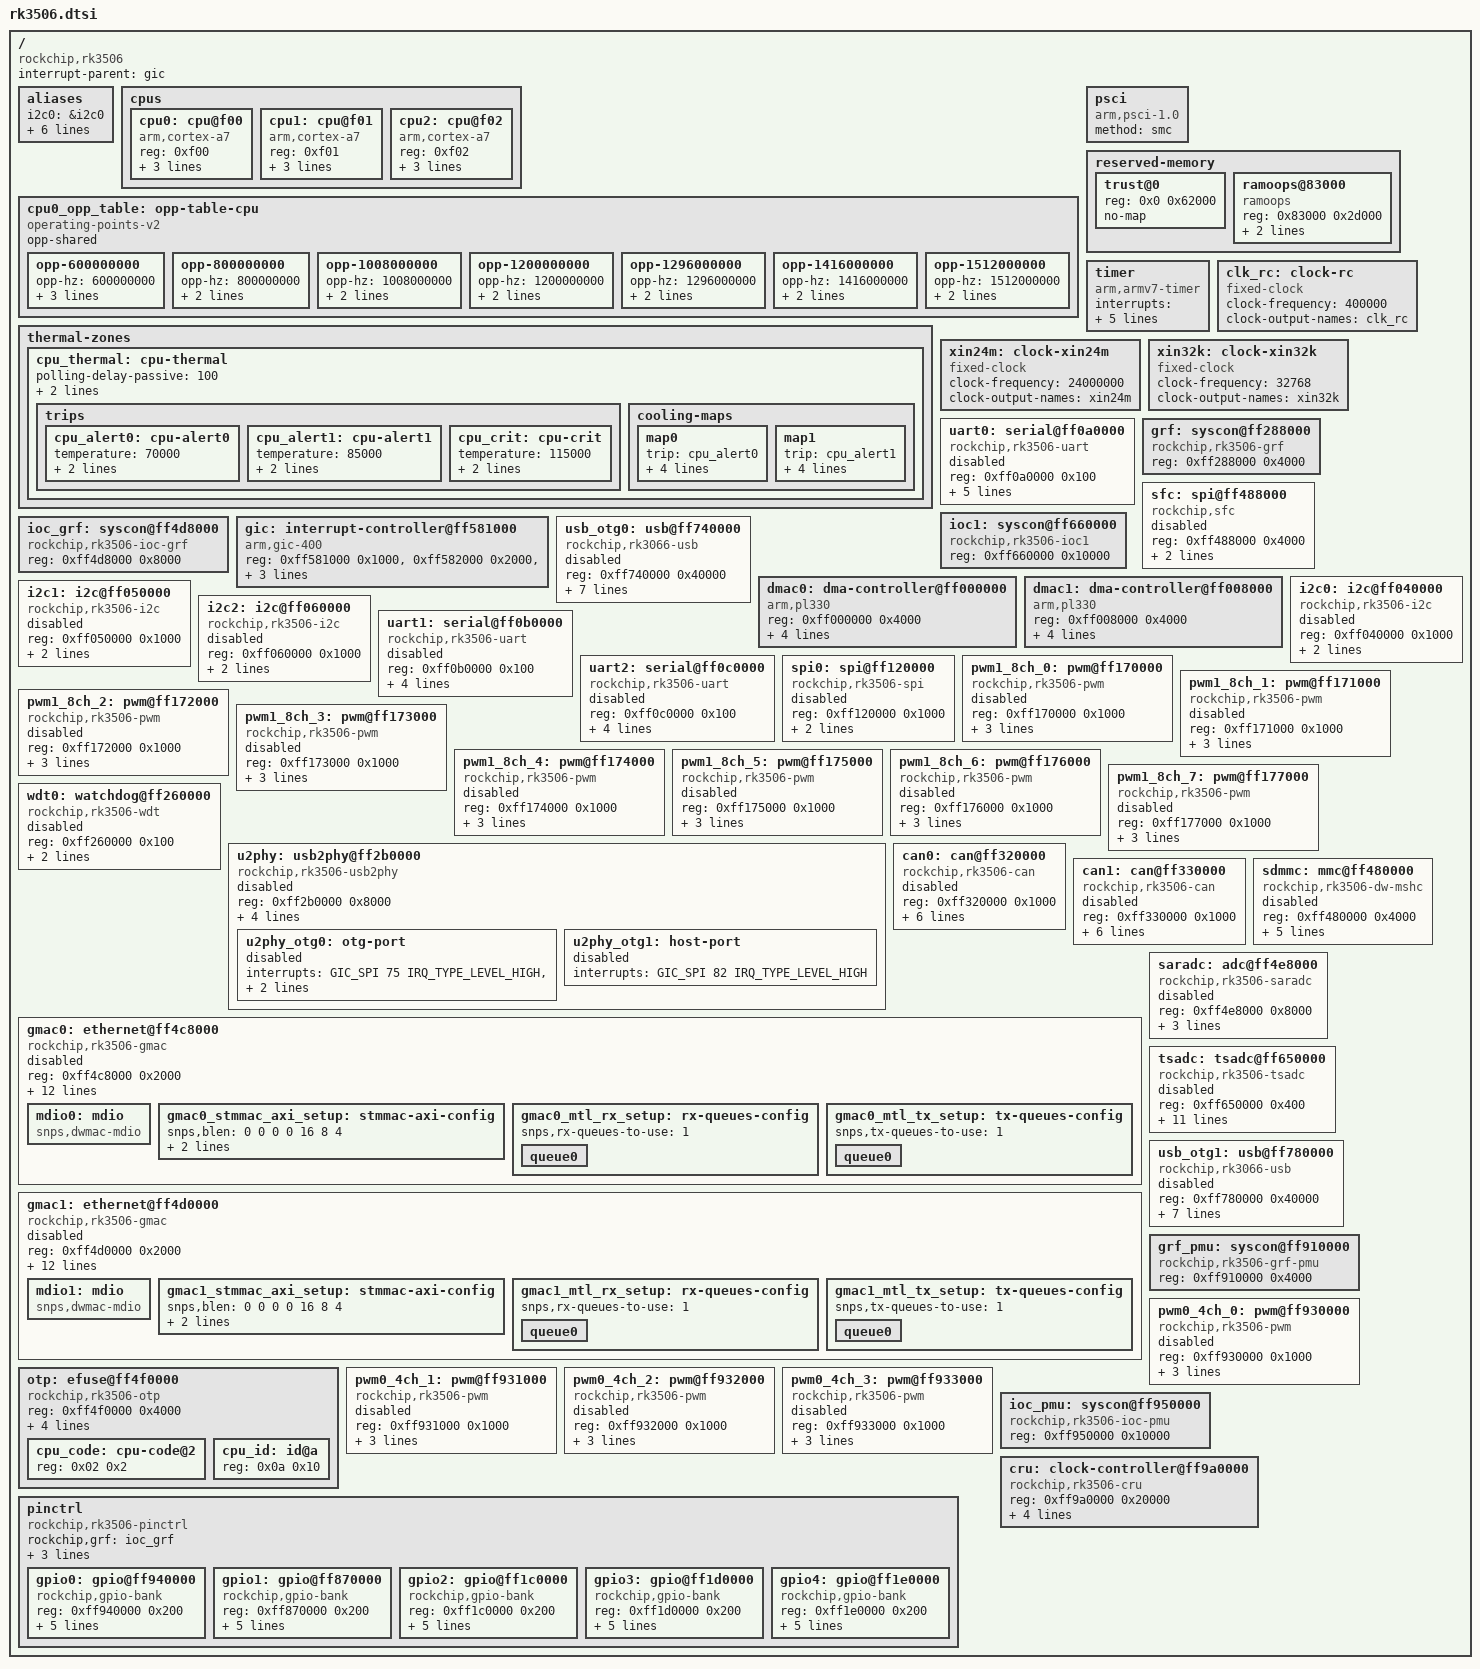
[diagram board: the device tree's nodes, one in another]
// SPDX-License-Identifier: (GPL-2.0+ OR MIT)
/*
 * Copyright (c) 2023 Rockchip Electronics Co., Ltd.
 *
 * Minimal RK3506 SoC description: only what is needed to reach a prompt on
 * the serial console. Transcribed from the vendor 6.1 kernel,
 * arch/arm/boot/dts/rk3502.dtsi (the real base dtsi there; rk3506.dtsi is a
 * thin wrapper on top of it).
 *
 * Deliberately absent: audio, PWM, mailbox, hwspinlock, USB, flexbus,
 * crypto, RNG, RGA, TSADC, SARADC, OTP, MMC, FSPI, DMA, I2C, SPI, uart1..5,
 * watchdog, OPP tables, PMU, thermal and the Rockchip-only suspend and
 * system-monitor nodes. Every one of those is a probe that can fail before
 * the console is up.
 */

#include <dt-bindings/clock/rockchip,rk3506-cru.h>
#include <dt-bindings/reset/rockchip,rk3506-cru.h>
#include <dt-bindings/gpio/gpio.h>
#include <dt-bindings/interrupt-controller/irq.h>
#include <dt-bindings/thermal/thermal.h>
#include <dt-bindings/interrupt-controller/arm-gic.h>
#include <dt-bindings/pinctrl/rockchip.h>

/ {
	#address-cells = <1>;
	#size-cells = <1>;

	compatible = "rockchip,rk3506";

	interrupt-parent = <&gic>;

	aliases {
		i2c0 = &i2c0;
		i2c1 = &i2c1;
		i2c2 = &i2c2;
		serial0 = &uart0;
		serial1 = &uart1;
		serial2 = &uart2;
		spi0 = &spi0;
	};

	cpus {
		#address-cells = <1>;
		#size-cells = <0>;

		cpu0: cpu@f00 {
			device_type = "cpu";
			compatible = "arm,cortex-a7";
			reg = <0xf00>;
			enable-method = "psci";
			clocks = <&cru ARMCLK>;
			operating-points-v2 = <&cpu0_opp_table>;
			#cooling-cells = <2>;
		};

		cpu1: cpu@f01 {
			device_type = "cpu";
			compatible = "arm,cortex-a7";
			reg = <0xf01>;
			enable-method = "psci";
			clocks = <&cru ARMCLK>;
			operating-points-v2 = <&cpu0_opp_table>;
			#cooling-cells = <2>;
		};

		cpu2: cpu@f02 {
			device_type = "cpu";
			compatible = "arm,cortex-a7";
			reg = <0xf02>;
			enable-method = "psci";
			clocks = <&cru ARMCLK>;
			operating-points-v2 = <&cpu0_opp_table>;
			#cooling-cells = <2>;
		};
	};

	/*
	 * The vendor tree's points and base voltages (it lowers them per chip
	 * from OTP data, which is not modelled here). armclk re-rates v1pll for
	 * each point and parks the cores on gpll meanwhile.
	 */
	cpu0_opp_table: opp-table-cpu {
		compatible = "operating-points-v2";
		opp-shared;

		opp-600000000 {
			opp-hz = /bits/ 64 <600000000>;
			opp-microvolt = <850000 850000 1207000>;
			clock-latency-ns = <40000>;
			opp-suspend;
		};

		opp-800000000 {
			opp-hz = /bits/ 64 <800000000>;
			opp-microvolt = <850000 850000 1207000>;
			clock-latency-ns = <40000>;
		};

		opp-1008000000 {
			opp-hz = /bits/ 64 <1008000000>;
			opp-microvolt = <850000 850000 1207000>;
			clock-latency-ns = <40000>;
		};

		opp-1200000000 {
			opp-hz = /bits/ 64 <1200000000>;
			opp-microvolt = <850000 850000 1207000>;
			clock-latency-ns = <40000>;
		};

		opp-1296000000 {
			opp-hz = /bits/ 64 <1296000000>;
			opp-microvolt = <900000 900000 1207000>;
			clock-latency-ns = <40000>;
		};

		opp-1416000000 {
			opp-hz = /bits/ 64 <1416000000>;
			opp-microvolt = <937500 937500 1207000>;
			clock-latency-ns = <40000>;
		};

		opp-1512000000 {
			opp-hz = /bits/ 64 <1512000000>;
			opp-microvolt = <975000 975000 1207000>;
			clock-latency-ns = <40000>;
		};
	};

	psci {
		compatible = "arm,psci-1.0";
		method = "smc";
	};

	thermal-zones {
		cpu_thermal: cpu-thermal {
			polling-delay-passive = <100>;
			polling-delay = <1000>;
			thermal-sensors = <&tsadc 0>;

			trips {
				cpu_alert0: cpu-alert0 {
					temperature = <70000>;
					hysteresis = <2000>;
					type = "passive";
				};
				cpu_alert1: cpu-alert1 {
					temperature = <85000>;
					hysteresis = <2000>;
					type = "passive";
				};
				cpu_crit: cpu-crit {
					temperature = <115000>;
					hysteresis = <2000>;
					type = "critical";
				};
			};

			cooling-maps {
				map0 {
					trip = <&cpu_alert0>;
					cooling-device = <&cpu0 THERMAL_NO_LIMIT THERMAL_NO_LIMIT>,
							 <&cpu1 THERMAL_NO_LIMIT THERMAL_NO_LIMIT>,
							 <&cpu2 THERMAL_NO_LIMIT THERMAL_NO_LIMIT>;
				};
				map1 {
					trip = <&cpu_alert1>;
					cooling-device = <&cpu0 THERMAL_NO_LIMIT THERMAL_NO_LIMIT>,
							 <&cpu1 THERMAL_NO_LIMIT THERMAL_NO_LIMIT>,
							 <&cpu2 THERMAL_NO_LIMIT THERMAL_NO_LIMIT>;
				};
			};
		};
	};

	reserved-memory {
		#address-cells = <1>;
		#size-cells = <1>;
		ranges;

		/*
		 * OP-TEE / TF-A. Do not remove: psci method = "smc" is served
		 * from here, so handing this range to the page allocator kills
		 * SMP bring-up and PSCI system-off.
		 *
		 * no-map because the range is not merely reserved, it is
		 * unreachable: the memory firewall rejects normal-world
		 * access, and even a read aborts. Measured from the U-Boot
		 * prompt, which also runs in normal world:
		 *
		 *     => md 0x4000 4
		 *     00004000:data abort
		 *
		 * The vendor node (rk3502.dtsi:335) omits no-map and so leaves
		 * the range in the kernel linear map, i.e. mappings that must
		 * never be touched.
		 */
		trust@0 {
			reg = <0x0 0x62000>;
			no-map;
		};

		/*
		 * The only way to read a panic that happened before the
		 * console was up. Vendor also sets boot-log-size and
		 * boot-log-count (rk3502.dtsi:352) - those are Rockchip
		 * extensions with no mainline binding, dropped here.
		 *
		 * The address is below the 2 MiB floor that
		 * linux,usable-memory-range establishes in the board dts, and
		 * that is fine: capping memblock removes the range from the
		 * allocator, not from reserved-memory. Verified on the board,
		 * pstore comes up and uses this region.
		 */
		ramoops@83000 {
			compatible = "ramoops";
			reg = <0x83000 0x2d000>;
			console-size = <0x20000>;
			record-size = <0x1000>;
		};
	};

	timer {
		compatible = "arm,armv7-timer";
		interrupts = <GIC_PPI 13 (GIC_CPU_MASK_SIMPLE(3) | IRQ_TYPE_LEVEL_HIGH)>,
			     <GIC_PPI 14 (GIC_CPU_MASK_SIMPLE(3) | IRQ_TYPE_LEVEL_HIGH)>,
			     <GIC_PPI 11 (GIC_CPU_MASK_SIMPLE(3) | IRQ_TYPE_LEVEL_HIGH)>,
			     <GIC_PPI 10 (GIC_CPU_MASK_SIMPLE(3) | IRQ_TYPE_LEVEL_HIGH)>;
		clock-frequency = <24000000>;
	};

	/*
	 * clk_rc, xin24m and xin32k are consumed by the CRU driver through
	 * their global names, not through a phandle, and the driver does not
	 * register them itself:
	 *   clk-rk3506.c:745  CLK_32K_RC ("clk_rc" parent, CLK_IS_CRITICAL)
	 *   clk-rk3506.c:175  XIN24M_GATE ("xin24m" parent, CLK_IS_CRITICAL)
	 *   clk-rk3506.c:145  clk_32k mux ("xin32k" parent)
	 * All three must therefore exist in DT even though no node here has a
	 * phandle to them. Vendor wraps them in a "clocks" simple-bus
	 * container (rk3502.dtsi:44); flattened to the root here, which is the
	 * mainline form and avoids dtc simple_bus_reg warnings. Same names,
	 * same rates, same labels.
	 */
	clk_rc: clock-rc {
		compatible = "fixed-clock";
		#clock-cells = <0>;
		clock-frequency = <400000>;
		clock-output-names = "clk_rc";
	};

	xin24m: clock-xin24m {
		compatible = "fixed-clock";
		#clock-cells = <0>;
		clock-frequency = <24000000>;
		clock-output-names = "xin24m";
	};

	xin32k: clock-xin32k {
		compatible = "fixed-clock";
		#clock-cells = <0>;
		clock-frequency = <32768>;
		clock-output-names = "xin32k";
	};

	uart0: serial@ff0a0000 {
		compatible = "rockchip,rk3506-uart", "snps,dw-apb-uart";
		reg = <0xff0a0000 0x100>;
		interrupts = <GIC_SPI 34 IRQ_TYPE_LEVEL_HIGH>;
		reg-shift = <2>;
		reg-io-width = <4>;
		clocks = <&cru SCLK_UART0>, <&cru PCLK_UART0>;
		clock-names = "baudclk", "apb_pclk";
		pinctrl-names = "default";
		pinctrl-0 = <&uart0_xfer_pins>;
		status = "disabled";
		/* vendor also wires dmas to dmac0; no DMA controller here */
	};

	grf: syscon@ff288000 {
		compatible = "rockchip,rk3506-grf", "syscon";
		reg = <0xff288000 0x4000>;
	};

	/*
	 * Serial flash controller. The vendor calls this block FSPI and gives
	 * it its own compatible ("rockchip,rk3506-fspi", "rockchip,fspi",
	 * rk3502.dtsi:942), but it keeps the SFC clock names, and the mainline
	 * binding states that the SFC is "a standalone IP with version
	 * register, and the driver can handle all the feature difference
	 * inside the IP depending on the version register". So describe it as
	 * rockchip,sfc and let spi-rockchip-sfc.c read SFC_VER.
	 *
	 * The vendor node also carries rockchip,grf and rockchip,max-dll,
	 * which the mainline binding does not define; left out.
	 */
	sfc: spi@ff488000 {
		compatible = "rockchip,sfc";
		reg = <0xff488000 0x4000>;
		interrupts = <GIC_SPI 85 IRQ_TYPE_LEVEL_HIGH>;
		clocks = <&cru SCLK_FSPI>, <&cru HCLK_FSPI>;
		clock-names = "clk_sfc", "hclk_sfc";
		#address-cells = <1>;
		#size-cells = <0>;
		status = "disabled";
	};

	/* pinctrl "rockchip,grf": iomux registers for the non-PMU banks */
	ioc_grf: syscon@ff4d8000 {
		compatible = "rockchip,rk3506-ioc-grf", "syscon";
		reg = <0xff4d8000 0x8000>;
	};

	gic: interrupt-controller@ff581000 {
		compatible = "arm,gic-400";
		reg = <0xff581000 0x1000>,
		      <0xff582000 0x2000>,
		      <0xff584000 0x2000>,
		      <0xff586000 0x2000>;
		interrupts = <GIC_PPI 9 IRQ_TYPE_LEVEL_HIGH>;
		#interrupt-cells = <3>;
		interrupt-controller;
		#address-cells = <0>;
	};

	/* pinctrl "rockchip,ioc1" */
	ioc1: syscon@ff660000 {
		compatible = "rockchip,rk3506-ioc1", "syscon";
		reg = <0xff660000 0x10000>;
	};

	/*
	 * OTG0, the USB port exposed on the board. No "phys" property: the
	 * RK3506 USB2 PHY is not supported by phy-rockchip-inno-usb2 yet, and
	 * dwc2 treats the PHY as optional (dwc2/platform.c, -ENODEV leaves
	 * hsotg->phy NULL and the probe continues).
	 *
	 * Only the "otg" clock is declared: dwc2.yaml allows just "otg" and
	 * "utmi", while the vendor also wires a "pmu" and an "adp" clock that
	 * mainline never touches.
	 *
	 * The compatible omits a "rockchip,rk3506-usb" first entry on purpose:
	 * dwc2.yaml enumerates the SoC-specific strings it accepts and rk3506
	 * is not among them, so adding it here without the binding change
	 * would only make dtbs_check fail.
	 */
	usb_otg0: usb@ff740000 {
		compatible = "rockchip,rk3066-usb", "snps,dwc2";
		reg = <0xff740000 0x40000>;
		interrupts = <GIC_SPI 74 IRQ_TYPE_LEVEL_HIGH>;
		clocks = <&cru HCLK_USBOTG0>;
		clock-names = "otg";
		dr_mode = "otg";
		g-np-tx-fifo-size = <16>;
		g-rx-fifo-size = <280>;
		g-tx-fifo-size = <256 128 128 64 32 16>;
		phys = <&u2phy_otg0>;
		phy-names = "usb2-phy";
		status = "disabled";
	};


	dmac0: dma-controller@ff000000 {
		compatible = "arm,pl330", "arm,primecell";
		reg = <0xff000000 0x4000>;
		interrupts = <GIC_SPI 116 IRQ_TYPE_LEVEL_HIGH>,
			     <GIC_SPI 117 IRQ_TYPE_LEVEL_HIGH>;
		clocks = <&cru ACLK_DMAC0>;
		clock-names = "apb_pclk";
		#dma-cells = <1>;
		arm,pl330-periph-burst;
	};

	dmac1: dma-controller@ff008000 {
		compatible = "arm,pl330", "arm,primecell";
		reg = <0xff008000 0x4000>;
		interrupts = <GIC_SPI 118 IRQ_TYPE_LEVEL_HIGH>,
			     <GIC_SPI 119 IRQ_TYPE_LEVEL_HIGH>;
		clocks = <&cru ACLK_DMAC1>;
		clock-names = "apb_pclk";
		#dma-cells = <1>;
		arm,pl330-periph-burst;
	};

	i2c0: i2c@ff040000 {
		compatible = "rockchip,rk3506-i2c", "rockchip,rk3399-i2c";
		reg = <0xff040000 0x1000>;
		interrupts = <GIC_SPI 40 IRQ_TYPE_LEVEL_HIGH>;
		clocks = <&cru CLK_I2C0>, <&cru PCLK_I2C0>;
		clock-names = "i2c", "pclk";
		#address-cells = <1>;
		#size-cells = <0>;
		status = "disabled";
	};

	i2c1: i2c@ff050000 {
		compatible = "rockchip,rk3506-i2c", "rockchip,rk3399-i2c";
		reg = <0xff050000 0x1000>;
		interrupts = <GIC_SPI 41 IRQ_TYPE_LEVEL_HIGH>;
		clocks = <&cru CLK_I2C1>, <&cru PCLK_I2C1>;
		clock-names = "i2c", "pclk";
		#address-cells = <1>;
		#size-cells = <0>;
		status = "disabled";
	};

	i2c2: i2c@ff060000 {
		compatible = "rockchip,rk3506-i2c", "rockchip,rk3399-i2c";
		reg = <0xff060000 0x1000>;
		interrupts = <GIC_SPI 42 IRQ_TYPE_LEVEL_HIGH>;
		clocks = <&cru CLK_I2C2>, <&cru PCLK_I2C2>;
		clock-names = "i2c", "pclk";
		#address-cells = <1>;
		#size-cells = <0>;
		status = "disabled";
	};

	uart1: serial@ff0b0000 {
		compatible = "rockchip,rk3506-uart", "snps,dw-apb-uart";
		reg = <0xff0b0000 0x100>;
		interrupts = <GIC_SPI 35 IRQ_TYPE_LEVEL_HIGH>;
		clocks = <&cru SCLK_UART1>, <&cru PCLK_UART1>;
		clock-names = "baudclk", "apb_pclk";
		reg-shift = <2>;
		reg-io-width = <4>;
		status = "disabled";
	};

	uart2: serial@ff0c0000 {
		compatible = "rockchip,rk3506-uart", "snps,dw-apb-uart";
		reg = <0xff0c0000 0x100>;
		interrupts = <GIC_SPI 36 IRQ_TYPE_LEVEL_HIGH>;
		clocks = <&cru SCLK_UART2>, <&cru PCLK_UART2>;
		clock-names = "baudclk", "apb_pclk";
		reg-shift = <2>;
		reg-io-width = <4>;
		status = "disabled";
	};

	spi0: spi@ff120000 {
		compatible = "rockchip,rk3506-spi", "rockchip,rk3066-spi";
		reg = <0xff120000 0x1000>;
		interrupts = <GIC_SPI 43 IRQ_TYPE_LEVEL_HIGH>;
		clocks = <&cru CLK_SPI0>, <&cru PCLK_SPI0>;
		clock-names = "spiclk", "apb_pclk";
		#address-cells = <1>;
		#size-cells = <0>;
		status = "disabled";
	};

	pwm1_8ch_0: pwm@ff170000 {
		compatible = "rockchip,rk3506-pwm", "rockchip,rk3576-pwm";
		reg = <0xff170000 0x1000>;
		clocks = <&cru CLK_PWM1>, <&cru PCLK_PWM1>, <&cru CLK_OSC_PWM1>,
			 <&cru CLK_RC_PWM1>;
		clock-names = "pwm", "pclk", "osc", "rc";
		interrupts = <GIC_SPI 26 IRQ_TYPE_LEVEL_HIGH>;
		#pwm-cells = <3>;
		status = "disabled";
	};

	pwm1_8ch_1: pwm@ff171000 {
		compatible = "rockchip,rk3506-pwm", "rockchip,rk3576-pwm";
		reg = <0xff171000 0x1000>;
		clocks = <&cru CLK_PWM1>, <&cru PCLK_PWM1>, <&cru CLK_OSC_PWM1>,
			 <&cru CLK_RC_PWM1>;
		clock-names = "pwm", "pclk", "osc", "rc";
		interrupts = <GIC_SPI 27 IRQ_TYPE_LEVEL_HIGH>;
		#pwm-cells = <3>;
		status = "disabled";
	};

	pwm1_8ch_2: pwm@ff172000 {
		compatible = "rockchip,rk3506-pwm", "rockchip,rk3576-pwm";
		reg = <0xff172000 0x1000>;
		clocks = <&cru CLK_PWM1>, <&cru PCLK_PWM1>, <&cru CLK_OSC_PWM1>,
			 <&cru CLK_RC_PWM1>;
		clock-names = "pwm", "pclk", "osc", "rc";
		interrupts = <GIC_SPI 28 IRQ_TYPE_LEVEL_HIGH>;
		#pwm-cells = <3>;
		status = "disabled";
	};

	pwm1_8ch_3: pwm@ff173000 {
		compatible = "rockchip,rk3506-pwm", "rockchip,rk3576-pwm";
		reg = <0xff173000 0x1000>;
		clocks = <&cru CLK_PWM1>, <&cru PCLK_PWM1>, <&cru CLK_OSC_PWM1>,
			 <&cru CLK_RC_PWM1>;
		clock-names = "pwm", "pclk", "osc", "rc";
		interrupts = <GIC_SPI 29 IRQ_TYPE_LEVEL_HIGH>;
		#pwm-cells = <3>;
		status = "disabled";
	};

	pwm1_8ch_4: pwm@ff174000 {
		compatible = "rockchip,rk3506-pwm", "rockchip,rk3576-pwm";
		reg = <0xff174000 0x1000>;
		clocks = <&cru CLK_PWM1>, <&cru PCLK_PWM1>, <&cru CLK_OSC_PWM1>,
			 <&cru CLK_RC_PWM1>;
		clock-names = "pwm", "pclk", "osc", "rc";
		interrupts = <GIC_SPI 30 IRQ_TYPE_LEVEL_HIGH>;
		#pwm-cells = <3>;
		status = "disabled";
	};

	pwm1_8ch_5: pwm@ff175000 {
		compatible = "rockchip,rk3506-pwm", "rockchip,rk3576-pwm";
		reg = <0xff175000 0x1000>;
		clocks = <&cru CLK_PWM1>, <&cru PCLK_PWM1>, <&cru CLK_OSC_PWM1>,
			 <&cru CLK_RC_PWM1>;
		clock-names = "pwm", "pclk", "osc", "rc";
		interrupts = <GIC_SPI 31 IRQ_TYPE_LEVEL_HIGH>;
		#pwm-cells = <3>;
		status = "disabled";
	};

	pwm1_8ch_6: pwm@ff176000 {
		compatible = "rockchip,rk3506-pwm", "rockchip,rk3576-pwm";
		reg = <0xff176000 0x1000>;
		clocks = <&cru CLK_PWM1>, <&cru PCLK_PWM1>, <&cru CLK_OSC_PWM1>,
			 <&cru CLK_RC_PWM1>;
		clock-names = "pwm", "pclk", "osc", "rc";
		interrupts = <GIC_SPI 32 IRQ_TYPE_LEVEL_HIGH>;
		#pwm-cells = <3>;
		status = "disabled";
	};

	pwm1_8ch_7: pwm@ff177000 {
		compatible = "rockchip,rk3506-pwm", "rockchip,rk3576-pwm";
		reg = <0xff177000 0x1000>;
		clocks = <&cru CLK_PWM1>, <&cru PCLK_PWM1>, <&cru CLK_OSC_PWM1>,
			 <&cru CLK_RC_PWM1>;
		clock-names = "pwm", "pclk", "osc", "rc";
		interrupts = <GIC_SPI 33 IRQ_TYPE_LEVEL_HIGH>;
		#pwm-cells = <3>;
		status = "disabled";
	};

	wdt0: watchdog@ff260000 {
		compatible = "rockchip,rk3506-wdt", "snps,dw-wdt";
		reg = <0xff260000 0x100>;
		interrupts = <GIC_SPI 107 IRQ_TYPE_LEVEL_HIGH>;
		clocks = <&cru TCLK_WDT0>, <&cru PCLK_WDT0>;
		clock-names = "tclk", "pclk";
		status = "disabled";
	};

	u2phy: usb2phy@ff2b0000 {
		compatible = "rockchip,rk3506-usb2phy";
		reg = <0xff2b0000 0x8000>;
		clocks = <&cru CLK_REF_USBPHY_TOP>, <&cru PCLK_USBPHY>;
		clock-names = "phyclk", "pclk";
		clock-output-names = "usb480m_phy";
		#clock-cells = <0>;
		rockchip,usbgrf = <&grf>;
		status = "disabled";

		u2phy_otg0: otg-port {
			#phy-cells = <0>;
			interrupts = <GIC_SPI 75 IRQ_TYPE_LEVEL_HIGH>,
				     <GIC_SPI 76 IRQ_TYPE_LEVEL_HIGH>,
				     <GIC_SPI 77 IRQ_TYPE_LEVEL_HIGH>;
			interrupt-names = "otg-bvalid", "otg-id", "linestate";
			status = "disabled";
		};

		u2phy_otg1: host-port {
			#phy-cells = <0>;
			interrupts = <GIC_SPI 82 IRQ_TYPE_LEVEL_HIGH>;
			interrupt-names = "linestate";
			status = "disabled";
		};
	};

	can0: can@ff320000 {
		compatible = "rockchip,rk3506-can", "rockchip,rk3576-can";
		reg = <0xff320000 0x1000>;
		interrupts = <GIC_SPI 45 IRQ_TYPE_LEVEL_HIGH>;
		clocks = <&cru CLK_CAN0>, <&cru HCLK_CAN0>;
		clock-names = "baudclk", "apb_pclk";
		/* keep the bit clock off v1pll, which cpufreq re-rates */
		assigned-clocks = <&cru CLK_CAN0>;
		assigned-clock-parents = <&cru CLK_V0PLL_GATE>;
		assigned-clock-rates = <300000000>;
		resets = <&cru SRST_CAN0>, <&cru SRST_H_CAN0>;
		reset-names = "can", "can-apb";
		status = "disabled";
	};

	can1: can@ff330000 {
		compatible = "rockchip,rk3506-can", "rockchip,rk3576-can";
		reg = <0xff330000 0x1000>;
		interrupts = <GIC_SPI 46 IRQ_TYPE_LEVEL_HIGH>;
		clocks = <&cru CLK_CAN1>, <&cru HCLK_CAN1>;
		clock-names = "baudclk", "apb_pclk";
		/* keep the bit clock off v1pll, which cpufreq re-rates */
		assigned-clocks = <&cru CLK_CAN1>;
		assigned-clock-parents = <&cru CLK_V0PLL_GATE>;
		assigned-clock-rates = <300000000>;
		resets = <&cru SRST_CAN1>, <&cru SRST_H_CAN1>;
		reset-names = "can", "can-apb";
		status = "disabled";
	};

	sdmmc: mmc@ff480000 {
		compatible = "rockchip,rk3506-dw-mshc", "rockchip,rk3288-dw-mshc";
		reg = <0xff480000 0x4000>;
		interrupts = <GIC_SPI 86 IRQ_TYPE_LEVEL_HIGH>;
		clocks = <&cru HCLK_SDMMC>, <&cru CCLK_SRC_SDMMC>;
		clock-names = "biu", "ciu";
		fifo-depth = <0x100>;
		max-frequency = <150000000>;
		resets = <&cru SRST_H_SDMMC>;
		reset-names = "reset";
		status = "disabled";
	};

	gmac0: ethernet@ff4c8000 {
		compatible = "rockchip,rk3506-gmac", "snps,dwmac-4.20a";
		reg = <0xff4c8000 0x2000>;
		interrupts = <GIC_SPI 66 IRQ_TYPE_LEVEL_HIGH>,
			     <GIC_SPI 69 IRQ_TYPE_LEVEL_HIGH>;
		interrupt-names = "macirq", "eth_wake_irq";
		clocks = <&cru CLK_MAC0>, <&cru CLK_MAC0_PTP>,
			 <&cru PCLK_MAC0>, <&cru ACLK_MAC0>,
			 <&cru CLK_MAC_OUT>;
		clock-names = "stmmaceth", "ptp_ref", "pclk_mac", "aclk_mac", "clk_mac_out";
		resets = <&cru SRST_A_MAC0>;
		reset-names = "stmmaceth";
		rockchip,grf = <&grf>;
		snps,axi-config = <&gmac0_stmmac_axi_setup>;
		snps,mixed-burst;
		snps,mtl-rx-config = <&gmac0_mtl_rx_setup>;
		snps,mtl-tx-config = <&gmac0_mtl_tx_setup>;
		snps,tso;
		status = "disabled";

		mdio0: mdio {
			compatible = "snps,dwmac-mdio";
			#address-cells = <0x1>;
			#size-cells = <0x0>;
		};

		gmac0_stmmac_axi_setup: stmmac-axi-config {
			snps,blen = <0 0 0 0 16 8 4>;
			snps,rd_osr_lmt = <8>;
			snps,wr_osr_lmt = <4>;
		};

		gmac0_mtl_rx_setup: rx-queues-config {
			snps,rx-queues-to-use = <1>;
			queue0 {};
		};

		gmac0_mtl_tx_setup: tx-queues-config {
			snps,tx-queues-to-use = <1>;
			queue0 {};
		};
	};

	gmac1: ethernet@ff4d0000 {
		compatible = "rockchip,rk3506-gmac", "snps,dwmac-4.20a";
		reg = <0xff4d0000 0x2000>;
		interrupts = <GIC_SPI 70 IRQ_TYPE_LEVEL_HIGH>,
			     <GIC_SPI 73 IRQ_TYPE_LEVEL_HIGH>;
		interrupt-names = "macirq", "eth_wake_irq";
		clocks = <&cru CLK_MAC1>, <&cru CLK_MAC1_PTP>,
			 <&cru PCLK_MAC1>, <&cru ACLK_MAC1>,
			 <&cru CLK_MAC_OUT>;
		clock-names = "stmmaceth", "ptp_ref", "pclk_mac", "aclk_mac", "clk_mac_out";
		resets = <&cru SRST_A_MAC1>;
		reset-names = "stmmaceth";
		rockchip,grf = <&grf>;
		snps,axi-config = <&gmac1_stmmac_axi_setup>;
		snps,mixed-burst;
		snps,mtl-rx-config = <&gmac1_mtl_rx_setup>;
		snps,mtl-tx-config = <&gmac1_mtl_tx_setup>;
		snps,tso;
		status = "disabled";

		mdio1: mdio {
			compatible = "snps,dwmac-mdio";
			#address-cells = <0x1>;
			#size-cells = <0x0>;
		};

		gmac1_stmmac_axi_setup: stmmac-axi-config {
			snps,blen = <0 0 0 0 16 8 4>;
			snps,rd_osr_lmt = <8>;
			snps,wr_osr_lmt = <4>;
		};

		gmac1_mtl_rx_setup: rx-queues-config {
			snps,rx-queues-to-use = <1>;
			queue0 {};
		};

		gmac1_mtl_tx_setup: tx-queues-config {
			snps,tx-queues-to-use = <1>;
			queue0 {};
		};
	};

	saradc: adc@ff4e8000 {
		compatible = "rockchip,rk3506-saradc", "rockchip,rk3528-saradc";
		reg = <0xff4e8000 0x8000>;
		interrupts = <GIC_SPI 57 IRQ_TYPE_LEVEL_HIGH>;
		clocks = <&cru CLK_SARADC>, <&cru PCLK_SARADC>;
		clock-names = "saradc", "apb_pclk";
		resets = <&cru SRST_P_SARADC>;
		reset-names = "saradc-apb";
		#io-channel-cells = <1>;
		status = "disabled";
	};

	otp: efuse@ff4f0000 {
		compatible = "rockchip,rk3506-otp";
		reg = <0xff4f0000 0x4000>;
		clocks = <&cru CLK_USER_OTPC_NS>, <&cru PCLK_OTPC_NS>,
			 <&cru CLK_SBPI_OTPC_NS>;
		clock-names = "otp", "apb_pclk", "sbpi";
		resets = <&cru SRST_USER_OTPC_NS>, <&cru SRST_P_OTPC_NS>,
			 <&cru SRST_SBPI_OTPC_NS>;
		reset-names = "otp", "apb", "sbpi";
		#address-cells = <1>;
		#size-cells = <1>;

		cpu_code: cpu-code@2 {
			reg = <0x02 0x2>;
		};

		cpu_id: id@a {
			reg = <0x0a 0x10>;
		};
	};

	tsadc: tsadc@ff650000 {
		compatible = "rockchip,rk3506-tsadc";
		reg = <0xff650000 0x400>;
		interrupts = <GIC_SPI 58 IRQ_TYPE_LEVEL_HIGH>;
		clocks = <&cru CLK_TSADC>, <&cru PCLK_TSADC>, <&cru CLK_TSADC_TSEN>;
		clock-names = "tsadc", "apb_pclk", "tsen";
		assigned-clocks = <&cru CLK_TSADC>, <&cru CLK_TSADC_TSEN>;
		assigned-clock-rates = <1000000>, <12000000>;
		resets = <&cru SRST_P_TSADC>, <&cru SRST_TSADC>;
		reset-names = "tsadc-apb", "tsadc";
		rockchip,grf = <&grf>;
		rockchip,hw-tshut-temp = <120000>;
		rockchip,hw-tshut-mode = <0>;
		rockchip,hw-tshut-polarity = <0>;
		#thermal-sensor-cells = <1>;
		status = "disabled";
	};

	usb_otg1: usb@ff780000 {
		compatible = "rockchip,rk3066-usb", "snps,dwc2";
		reg = <0xff780000 0x40000>;
		interrupts = <GIC_SPI 79 IRQ_TYPE_LEVEL_HIGH>;
		clocks = <&cru HCLK_USBOTG1>;
		clock-names = "otg";
		dr_mode = "otg";
		g-np-tx-fifo-size = <16>;
		g-rx-fifo-size = <280>;
		g-tx-fifo-size = <256 128 128 64 32 16>;
		phys = <&u2phy_otg1>;
		phy-names = "usb2-phy";
		status = "disabled";
	};

	/*
	 * pinctrl "rockchip,rmio". Mandatory for this SoC:
	 * pinctrl-rockchip.c returns -EINVAL when the phandle is missing,
	 * because rk3506_pin_ctrl declares one rmio region.
	 * The vendor reboot-mode child is dropped (needs
	 * <dt-bindings/soc/rockchip,boot-mode.h> and adds nothing to a
	 * console bring-up).
	 */
	grf_pmu: syscon@ff910000 {
		compatible = "rockchip,rk3506-grf-pmu", "syscon";
		reg = <0xff910000 0x4000>;
	};

	pwm0_4ch_0: pwm@ff930000 {
		compatible = "rockchip,rk3506-pwm", "rockchip,rk3576-pwm";
		reg = <0xff930000 0x1000>;
		clocks = <&cru CLK_PWM0>, <&cru PCLK_PWM0>, <&cru CLK_OSC_PWM0>,
			 <&cru CLK_RC_PWM0>;
		clock-names = "pwm", "pclk", "osc", "rc";
		interrupts = <GIC_SPI 22 IRQ_TYPE_LEVEL_HIGH>;
		#pwm-cells = <3>;
		status = "disabled";
	};

	pwm0_4ch_1: pwm@ff931000 {
		compatible = "rockchip,rk3506-pwm", "rockchip,rk3576-pwm";
		reg = <0xff931000 0x1000>;
		clocks = <&cru CLK_PWM0>, <&cru PCLK_PWM0>, <&cru CLK_OSC_PWM0>,
			 <&cru CLK_RC_PWM0>;
		clock-names = "pwm", "pclk", "osc", "rc";
		interrupts = <GIC_SPI 23 IRQ_TYPE_LEVEL_HIGH>;
		#pwm-cells = <3>;
		status = "disabled";
	};

	pwm0_4ch_2: pwm@ff932000 {
		compatible = "rockchip,rk3506-pwm", "rockchip,rk3576-pwm";
		reg = <0xff932000 0x1000>;
		clocks = <&cru CLK_PWM0>, <&cru PCLK_PWM0>, <&cru CLK_OSC_PWM0>,
			 <&cru CLK_RC_PWM0>;
		clock-names = "pwm", "pclk", "osc", "rc";
		interrupts = <GIC_SPI 24 IRQ_TYPE_LEVEL_HIGH>;
		#pwm-cells = <3>;
		status = "disabled";
	};

	pwm0_4ch_3: pwm@ff933000 {
		compatible = "rockchip,rk3506-pwm", "rockchip,rk3576-pwm";
		reg = <0xff933000 0x1000>;
		clocks = <&cru CLK_PWM0>, <&cru PCLK_PWM0>, <&cru CLK_OSC_PWM0>,
			 <&cru CLK_RC_PWM0>;
		clock-names = "pwm", "pclk", "osc", "rc";
		interrupts = <GIC_SPI 25 IRQ_TYPE_LEVEL_HIGH>;
		#pwm-cells = <3>;
		status = "disabled";
	};

	/* pinctrl "rockchip,pmu": iomux registers for the PMU bank (gpio0) */
	ioc_pmu: syscon@ff950000 {
		compatible = "rockchip,rk3506-ioc-pmu", "syscon";
		reg = <0xff950000 0x10000>;
	};

	cru: clock-controller@ff9a0000 {
		compatible = "rockchip,rk3506-cru";
		reg = <0xff9a0000 0x20000>;
		clocks = <&xin24m>;
		clock-names = "xin";
		#clock-cells = <1>;
		#reset-cells = <1>;

		/*
		 * Kept from the vendor node: SCLK_UART0 can only reach
		 * 1500000 baud through one of these fractional matrices.
		 */
		assigned-clocks =
			<&cru CLK_FRAC_UART_MATRIX0>,
			<&cru CLK_FRAC_UART_MATRIX1>;
		assigned-clock-rates =
			<96000000>,
			<128000000>;
	};

	pinctrl: pinctrl {
		compatible = "rockchip,rk3506-pinctrl";
		rockchip,grf = <&ioc_grf>;
		rockchip,ioc1 = <&ioc1>;
		rockchip,pmu = <&ioc_pmu>;
		rockchip,rmio = <&grf_pmu>;
		#address-cells = <1>;
		#size-cells = <1>;
		ranges;

		gpio0: gpio@ff940000 {
			compatible = "rockchip,gpio-bank";
			reg = <0xff940000 0x200>;
			interrupts = <GIC_SPI 0 IRQ_TYPE_LEVEL_HIGH>;
			clocks = <&cru PCLK_GPIO0>, <&cru DBCLK_GPIO0>;

			gpio-controller;
			#gpio-cells = <2>;
			gpio-ranges = <&pinctrl 0 0 32>;
			interrupt-controller;
			#interrupt-cells = <2>;
		};

		gpio1: gpio@ff870000 {
			compatible = "rockchip,gpio-bank";
			reg = <0xff870000 0x200>;
			interrupts = <GIC_SPI 4 IRQ_TYPE_LEVEL_HIGH>;
			clocks = <&cru PCLK_GPIO1>, <&cru DBCLK_GPIO1>;

			gpio-controller;
			#gpio-cells = <2>;
			gpio-ranges = <&pinctrl 0 32 32>;
			interrupt-controller;
			#interrupt-cells = <2>;
		};

		gpio2: gpio@ff1c0000 {
			compatible = "rockchip,gpio-bank";
			reg = <0xff1c0000 0x200>;
			interrupts = <GIC_SPI 8 IRQ_TYPE_LEVEL_HIGH>;
			clocks = <&cru PCLK_GPIO2>, <&cru DBCLK_GPIO2>;

			gpio-controller;
			#gpio-cells = <2>;
			gpio-ranges = <&pinctrl 0 64 32>;
			interrupt-controller;
			#interrupt-cells = <2>;
		};

		gpio3: gpio@ff1d0000 {
			compatible = "rockchip,gpio-bank";
			reg = <0xff1d0000 0x200>;
			interrupts = <GIC_SPI 12 IRQ_TYPE_LEVEL_HIGH>;
			clocks = <&cru PCLK_GPIO3>, <&cru DBCLK_GPIO3>;

			gpio-controller;
			#gpio-cells = <2>;
			gpio-ranges = <&pinctrl 0 96 32>;
			interrupt-controller;
			#interrupt-cells = <2>;
		};

		gpio4: gpio@ff1e0000 {
			compatible = "rockchip,gpio-bank";
			reg = <0xff1e0000 0x200>;
			interrupts = <GIC_SPI 16 IRQ_TYPE_LEVEL_HIGH>;
			clocks = <&cru PCLK_GPIO4>, <&cru DBCLK_GPIO4>;

			gpio-controller;
			#gpio-cells = <2>;
			gpio-ranges = <&pinctrl 0 128 32>;
			interrupt-controller;
			#interrupt-cells = <2>;
		};
	};
};

#include "rk3506-pinctrl.dtsi"
#include "rk3506-pinctrl-rmio.dtsi"
